VERSION ""

NS_ :

BS_:

BU_:
VAL_TABLE_ Fail_Grade 3 "Shut down MCU" 2 "Zero torque output" 1 "Warning derated" 0 "No Fault" ;
VAL_TABLE_ Hill_hold 3 "Error" 2 "Reserved" 1 "Hill hold active" 0 "Hill hold Inactive" ;

BO_ 3221225472 VECTOR__INDEPENDENT_SIG_MSG: 0 Vector__XXX
 SG_ msg6_check : 0|4@1+ (1,0) [0|15] "" Vector__XXX
 SG_ msg4_check : 0|4@1+ (1,0) [0|15] "" Vector__XXX
 SG_ msg3_check : 0|4@1+ (1,0) [0|15] "" Vector__XXX
 SG_ msg5_check : 0|4@1+ (1,0) [0|255] "" Vector__XXX
 SG_ msg2_check : 0|4@1+ (1,0) [0|15] "" Vector__XXX
 SG_ msg1_check : 0|4@1+ (1,0) [0|15] "" Vector__XXX
 SG_ New_Signal_52 : 0|8@1+ (1,0) [0|0] "" Vector__XXX
 SG_ New_Signal_50 : 0|8@1+ (1,0) [0|0] "" Vector__XXX

BO_ 264 ResIPData_02: 8 Vector__XXX
 SG_ Resistor_IP_16 : 39|32@0- (1,0) [-2147483648|2147483647] "" Vector__XXX
 SG_ Resistor_IP_06 : 7|32@0- (1,0) [-2147483648|2147483647] "" Vector__XXX

BO_ 263 ResIPData_01: 8 Vector__XXX
 SG_ Resistor_IP_18 : 39|32@0- (1,0) [-2147483648|2147483647] "" Vector__XXX
 SG_ Resistor_IP_17 : 7|32@0- (1,0) [-2147483648|2147483647] "" Vector__XXX

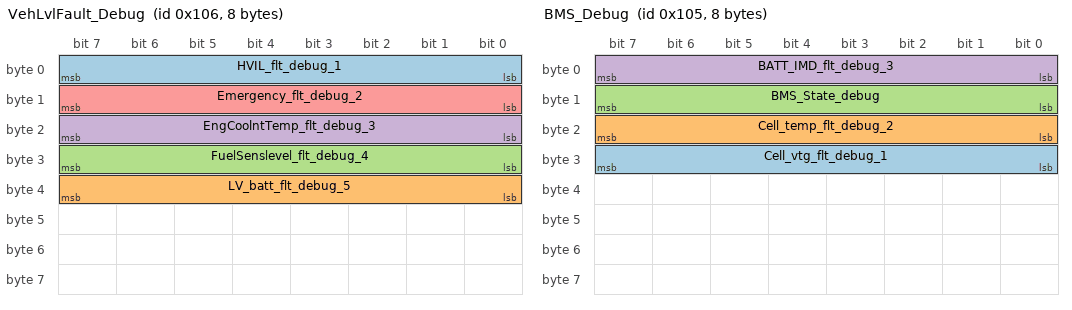
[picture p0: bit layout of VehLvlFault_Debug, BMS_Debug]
BO_ 262 VehLvlFault_Debug: 8 Vector__XXX
 SG_ HVIL_flt_debug_1 : 7|8@0+ (1,0) [0|255] "" Vector__XXX
 SG_ LV_batt_flt_debug_5 : 39|8@0+ (1,0) [0|255] "" Vector__XXX
 SG_ FuelSenslevel_flt_debug_4 : 31|8@0+ (1,0) [0|255] "" Vector__XXX
 SG_ EngCoolntTemp_flt_debug_3 : 23|8@0+ (1,0) [0|255] "" Vector__XXX
 SG_ Emergency_flt_debug_2 : 15|8@0+ (1,0) [0|255] "" Vector__XXX

BO_ 261 BMS_Debug: 8 Vector__XXX
 SG_ Cell_vtg_flt_debug_1 : 31|8@0+ (1,0) [0|255] "" Vector__XXX
 SG_ Cell_temp_flt_debug_2 : 23|8@0+ (1,0) [0|255] "" Vector__XXX
 SG_ BMS_State_debug : 15|8@0+ (1,0) [0|255] "" Vector__XXX
 SG_ BATT_IMD_flt_debug_3 : 7|8@0+ (1,0) [0|255] "" Vector__XXX

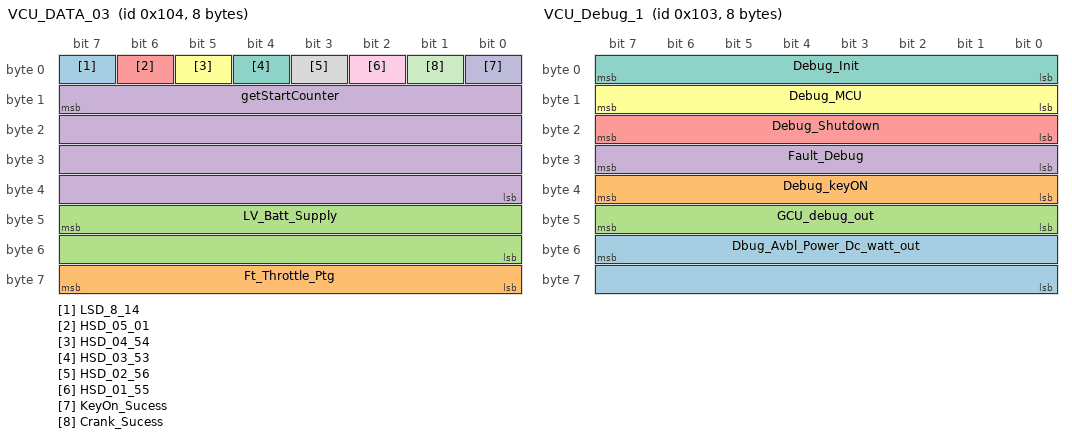
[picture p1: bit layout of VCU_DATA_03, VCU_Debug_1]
BO_ 260 VCU_DATA_03: 8 Vector__XXX
 SG_ LSD_8_14 : 7|1@1+ (1,0) [0|1] "" Vector__XXX
 SG_ Ft_Throttle_Ptg : 63|8@0- (1,0) [-128|127] "" Vector__XXX
 SG_ LV_Batt_Supply : 47|16@0+ (1,0) [0|65535] "" Vector__XXX
 SG_ getStartCounter : 15|32@0+ (1,0) [0|4294967295] "" Vector__XXX
 SG_ HSD_05_01 : 6|1@0+ (1,0) [0|1] "" Vector__XXX
 SG_ HSD_04_54 : 5|1@0+ (1,0) [0|1] "" Vector__XXX
 SG_ HSD_03_53 : 4|1@0+ (1,0) [0|1] "" Vector__XXX
 SG_ HSD_02_56 : 3|1@0+ (1,0) [0|1] "" Vector__XXX
 SG_ HSD_01_55 : 2|1@0+ (1,0) [0|1] "" Vector__XXX
 SG_ KeyOn_Sucess : 0|1@0+ (1,0) [0|1] "" Vector__XXX
 SG_ Crank_Sucess : 1|1@0+ (1,0) [0|1] "" Vector__XXX

BO_ 259 VCU_Debug_1: 8 Vector__XXX
 SG_ Dbug_Avbl_Power_Dc_watt_out : 55|16@0- (1,0) [-32768|32767] "" Vector__XXX
 SG_ Debug_keyON : 39|8@0+ (1,0) [0|255] "" Vector__XXX
 SG_ GCU_debug_out : 47|8@0+ (1,0) [0|255] "" Vector__XXX
 SG_ Fault_Debug : 31|8@0+ (1,0) [0|255] "" Vector__XXX
 SG_ Debug_Shutdown : 23|8@0+ (1,0) [0|255] "" Vector__XXX
 SG_ Debug_MCU : 15|8@0+ (1,0) [0|255] "" Vector__XXX
 SG_ Debug_Init : 7|8@0+ (1,0) [0|255] "" Vector__XXX

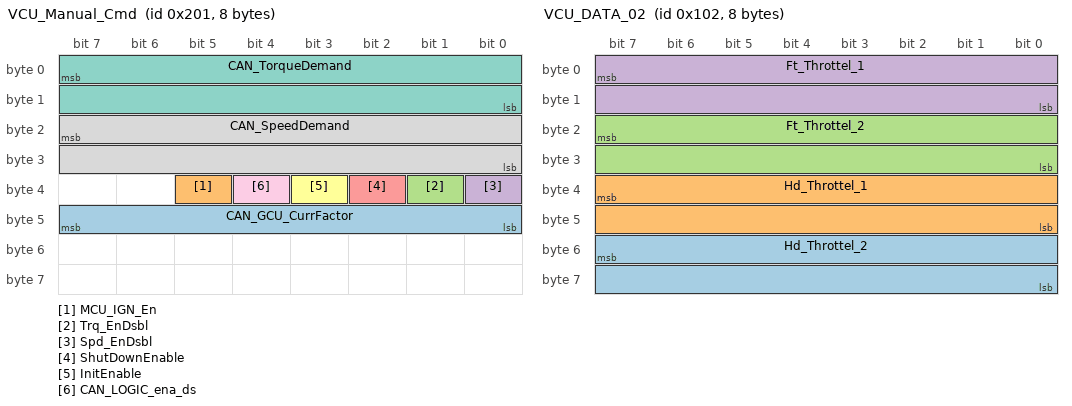
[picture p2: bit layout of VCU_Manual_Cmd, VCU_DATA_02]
BO_ 513 VCU_Manual_Cmd: 8 Vector__XXX
 SG_ CAN_GCU_CurrFactor : 40|8@1- (1,0) [-128|127] "" Vector__XXX
 SG_ MCU_IGN_En : 37|1@0+ (1,0) [0|1] "" Vector__XXX
 SG_ Trq_EnDsbl : 33|1@0+ (1,0) [0|1] "" Vector__XXX
 SG_ Spd_EnDsbl : 32|1@0+ (1,0) [0|1] "" Vector__XXX
 SG_ ShutDownEnable : 34|1@0+ (1,0) [0|1] "" Vector__XXX
 SG_ InitEnable : 35|1@0+ (1,0) [0|1] "" Vector__XXX
 SG_ CAN_TorqueDemand : 7|16@0+ (1,0) [0|65535] "" Vector__XXX
 SG_ CAN_SpeedDemand : 23|16@0+ (1,0) [0|65535] "" Vector__XXX
 SG_ CAN_LOGIC_ena_ds : 36|1@0+ (1,0) [0|1] "" Vector__XXX

BO_ 258 VCU_DATA_02: 8 Vector__XXX
 SG_ Hd_Throttel_2 : 55|16@0- (1,0) [0|0] "" Vector__XXX
 SG_ Hd_Throttel_1 : 39|16@0- (1,0) [-32768|32767] "" Vector__XXX
 SG_ Ft_Throttel_2 : 23|16@0- (1,0) [-32768|32767] "" Vector__XXX
 SG_ Ft_Throttel_1 : 7|16@0- (1,0) [-32768|32767] "" Vector__XXX

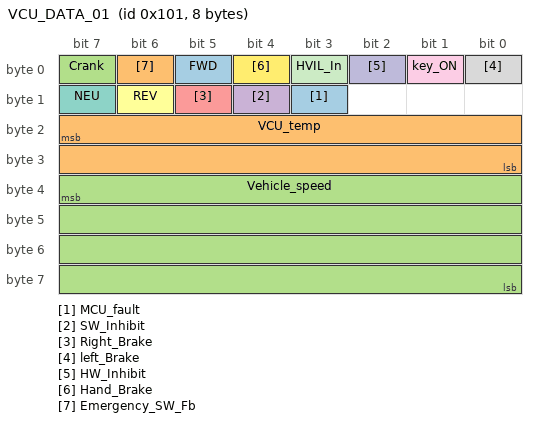
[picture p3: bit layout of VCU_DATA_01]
BO_ 257 VCU_DATA_01: 8 Vector__XXX
 SG_ MCU_fault : 11|1@0+ (1,0) [0|1] "" Vector__XXX
 SG_ VCU_temp : 23|16@0- (1,0) [-32768|32767] "" Vector__XXX
 SG_ Vehicle_speed : 39|32@0+ (1,0) [0|4294967295] "" Vector__XXX
 SG_ SW_Inhibit : 12|1@0+ (1,0) [0|1] "" Vector__XXX
 SG_ Right_Brake : 13|1@0+ (1,0) [0|1] "" Vector__XXX
 SG_ REV : 14|1@0+ (1,0) [0|1] "" Vector__XXX
 SG_ NEU : 15|1@0+ (1,0) [0|1] "" Vector__XXX
 SG_ left_Brake : 0|1@0+ (1,0) [0|1] "" Vector__XXX
 SG_ key_ON : 1|1@0+ (1,0) [0|0] "" Vector__XXX
 SG_ HW_Inhibit : 2|1@0+ (1,0) [0|1] "" Vector__XXX
 SG_ HVIL_In : 3|1@0+ (1,0) [0|1] "" Vector__XXX
 SG_ Hand_Brake : 4|1@0+ (1,0) [0|1] "" Vector__XXX
 SG_ FWD : 5|1@0+ (1,0) [0|1] "" Vector__XXX
 SG_ Emergency_SW_Fb : 6|1@0+ (1,0) [0|1] "" Vector__XXX
 SG_ Crank : 7|1@0+ (1,0) [0|1] "" Vector__XXX

CM_ BO_ 3221225472 "This is a message for not used signals, created by Vector CANdb++ DBC OLE DB Provider.";
BA_DEF_  "BusType" STRING ;
BA_DEF_DEF_  "BusType" "CAN";
